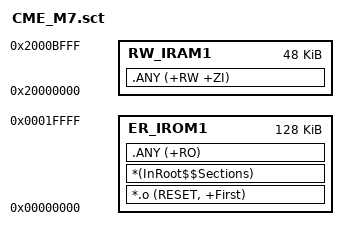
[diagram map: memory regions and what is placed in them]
; *************************************************************
; *** Scatter-Loading Description File generated by uVision ***
; *************************************************************

; load      region          size_region
LR_IROM1    (0)             (1024 * 128)
{
    ; load address = execution address
    ER_IROM1 (0)            (1024 * 128)
    {
        *.o (RESET, +First)
        *(InRoot$$Sections)
        .ANY (+RO)
    }

    ; RW data
    RW_IRAM1 0x20000000 (1024 * 48)
    {
        .ANY (+RW +ZI)
    }
}

